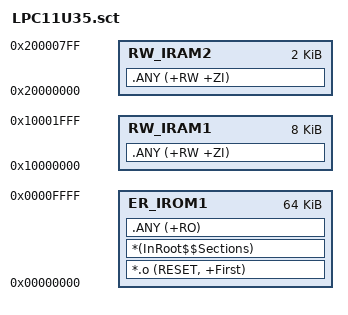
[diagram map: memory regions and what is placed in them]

LR_IROM1 0x00000000 0x10000  {    ; load region size_region (64k)

  ER_IROM1 0x00000000 0x10000  {  ; load address = execution address
   *.o (RESET, +First)
   *(InRoot$$Sections)
   .ANY (+RO)
  }
  
  ; Main SRAM
  RW_IRAM1 0x10000000 0x2000  {
   .ANY (+RW +ZI)
  }
  
  ;I/O Handler RAM
  RW_IRAM2 0x20000000 0x0800  {
   .ANY (+RW +ZI)
  }
  
}
